# SN32F290 register map
Vendor: SONIX; File version: 2026.10.03
CPU: CM0 r0p0, little endian, no MPU, no FPU, 2 interrupt priority bits
Registers are 32-bit, read-write, reset 0x0 unless marked. A register's access mark holds for its fields unless they carry their own. Offsets are from the block's base; [hi:lo] are bit positions.

## SN_SPI0 — SPI0
Base 0x4001C000
0x00 CTRL0 reset 0x40F00 (reset mask 0x7FFDF) — Offset:0x00 SPI0 Control Register 0
  [36:18] SELDIS — Auto-SEL disable bit
    0=Enable_145 (Enable Auto-SEL flow control); 1=Disable_434 (Disable Auto-SEL flow control)
  [32:15] RXFIFOTH — RX FIFO Threshold level
    0=V_0_164 (RX FIFO threshold level is 0); 1=V_1_374 (RX FIFO threshold level is 1); 2=V_2 (RX FIFO threshold level is 2); 3=V_3_20 (RX FIFO threshold level is 3); 4=V_4_16 (RX FIFO threshold level is 4); 5=V_5 (RX FIFO threshold level is 5); 6=V_6_9 (RX FIFO threshold level is 6); 7=V_7_10 (RX FIFO threshold level is 7)
  [26:12] TXFIFOTH — TX FIFO Threshold level
    0=V_0_164 (TX FIFO threshold level is 0); 1=V_1_374 (TX FIFO threshold level is 1); 2=V_2 (TX FIFO threshold level is 2); 3=V_3_20 (TX FIFO threshold level is 3); 4=V_4_16 (TX FIFO threshold level is 4); 5=V_5 (TX FIFO threshold level is 5); 6=V_6_9 (TX FIFO threshold level is 6); 7=V_7_10 (TX FIFO threshold level is 7)
  [19:8] DL — Data length = DL[3:0]+1
    10=V_1010_2 (Data length=11); 11=V_1011_2 (Data length=12); 12=V_1100_6 (Data length=13); 13=V_1101_3 (Data length=14); 14=V_1110_5 (Data length=15); 15=V_1111 (Data length=16); 2=V_0010_2 (Data length=3); 3=V_0011_4 (Data length=4); 4=V_0100_6 (Data length=5); 5=V_0101_4 (Data length=6); 6=V_0110 (Data length=7); 7=V_0111_5 (Data length=8); 8=V_1000_3 (Data length=9); 9=V_1001_3 (Data length=10)
  [13:6] FRESET wo — SPI FSM and FIFO Reset
    0=V_00 (No effect); 3=V_11_3 (Reset FSM and FIFO)
  [8:4] FORMAT — Interface format
    0=SPI_2 (SPI format)
  [6:3] MS — Master/Slave selection
    0=Master_3 (Act as Master); 1=Slave_6 (Act as Slave)
  [4:2] SDODIS — Slave data out disable
    0=Enable_145 (Enable slave data out); 1=Disble_2 (Diable slave data out (MISO=0))
  [2:1] LOOPBACK — Loopback mode enable
    0=Disable_434 (Disable loopback mode); 1=Enable_145 (Enable loopback mode)
  [0] SPIEN — SPI enable
    0=Disable_434 (Disable SPI); 1=Enable_145 (Enable SPI)
0x04 CTRL1 (reset mask 0x7) — Offset:0x04 SPI0 Control Register 1
  [4:2] CPHA — Clock phase of edge sampling
    0=CPHA0_2 (The 1st bit is fixed already, and SCK 1st edge is to receive/transmit data); 1=CPHA1_2 (SCK 1st edge is for data transition, and receive/transmit data at 2nd edge)
  [2:1] CPOL — Clock priority selection
    0=Low_4 (SCK idles at low level); 1=High_23 (SCK idles at high level)
  [0] MLSB — MSB/LSB seletion
    0=MSB_2 (MSB transmit first); 1=LSB_2 (LSB transmit first)
0x08 CLKDIV — Offset:0x08 SPI0 Clock Divider Register
  [7:0] DIV — SPI0 SCK
0x0C STAT ro reset 0x25 (reset mask 0x7F) — Offset:0x0C SPI0 Status Register
  [12:6] RXFIFOTHF — RX FIFO threshold flag
    0=V_0_164 (Data count in RX FIFO is less equal than RXFIFOTH); 1=V_1_374 (Data count in RX FIFO is larger than RXFIFOTH)
  [10:5] TXFIFOTHF — TX FIFO threshold flag
    0=V_0_164 (Data count in TX FIFO is larger than TXFIFOTH); 1=V_1_374 (Data count in TX FIFO is less equal than TXFIFOTH)
  [8:4] BUSY — Busy flag
    0=Idle_6 (SSPn is idle); 1=SSPn is transfering
  [6:3] RX_FULL — RX FIFO full flag
    0=V_0_164 (RX FIFO is not full); 1=V_1_374 (RX FIFO is full)
  [4:2] RX_EMPTY — RX FIFO empty flag
    0=V_0_164 (RX FIFO is not empty); 1=V_1_374 (RX FIFO is empty)
  [2:1] TX_FULL — TX FIFO full flag
    0=V_0_164 (TX FIFO is not full); 1=V_1_374 (TX FIFO is full)
  [0] TX_EMPTY — TX FIFO empty flag
    0=V_0_164 (TX FIFO is not empty); 1=V_1_374 (TX FIFO is empty)
0x10 IE (reset mask 0x3F) — Offset:0x10 SPI0 Interrupt Enable Register
  [10:5] DMATCIE — DMA transfer complete interrupt enable bit
    0=Disable_434 (Disable DMA transfer complete interrupt); 1=Enable_145 (Enable DMA transfer complete interrupt)
  [8:4] DMAHTIE — DMA half transfer interrupt enable bit
    0=Disable_434 (Disable DMA half transfer interrupt); 1=Enable_145 (Enable DMA half transfer interrupt)
  [6:3] TXFIFOTHIE — TX FIFO threshold interrupt enable
    0=Disable_434 (Disable TX FIFO threshold interrupt); 1=Enable_145 (Enable TX FIFO threshold interrupt)
  [4:2] RXFIFOTHIE — RX FIFO threshold interrupt enable
    0=Disable_434 (Disable RX FIFO threshold interrupt); 1=Enable_145 (Enable RX FIFO threshold interrupt)
  [2:1] RXTOIE — RX time-out interrupt enable
    0=Disable_434 (Disable RX time-out interrupt); 1=Enable_145 (Enable RX time-out interrupt)
  [0] RXOVFIE — RX FIFO overflow interrupt enable
    0=Disable_434 (Disable RX FIFO overflow interrupt); 1=Enable_145 (Enable RX FIFO overflow interrupt)
0x14 RIS ro (reset mask 0x3F) — Offset:0x14 SPI0 Raw Interrupt Status Register
  [10:5] DMATCIF — DMA transfer complete flag
    0=No_58 (No transfer completion); 1=Met_12 (A transfer complete event occurs)
  [8:4] DMAHTIF — RX FIFO threshold interrupt flag
    0=No_58 (No half transfer event); 1=Met_12 (A half transfer event occurs)
  [6:3] TXFIFOTHIF — TX FIFO threshold interrupt flag
    0=No_58 (No TXFIFOTH interrupt); 1=Met_12 (TX FIFO threshold is triggered when TXFIFOTHIE=1)
  [4:2] RXFIFOTHIF — RX FIFO threshold interrupt flag
    0=No_58 (No RXFIFOTH interrupt); 1=Met_12 (RX FIFO threshold is triggered when RXFIFOTHIE=1)
  [2:1] RXTOIF — RX time-out interrupt flag
    0=No_58 (No RXTO interrupt); 1=Met_12 (RXTO interrupt is triggered when RXTOIE=1)
  [0] RXOVFIF — RX FIFO overflow interrupt flag
    0=No_58 (No RXOVF interrupt); 1=Met_12 (RXOVF interrupt is triggered when RXOVFIE=1)
0x18 IC wo (reset mask 0x3F) — Offset:0x18 SPI0 Interrupt Clear Register
  [10:5] DMATCIC — Select the DMATCIF flag to be cleared
    0=No_effect_200; 1=Clear_V_150 (Clear DMATCIF flag)
  [8:4] DMAHTIC — Select the DMAHTIF flag to be cleared
    0=No_effect_200; 1=Clear_V_150 (Clear DMAHTIF flag)
  [6:3] TXFIFOTHIC — TX Interrupt flag Clear
    0=No_effect_200; 1=Clear_V_150 (Clear TXFIFOTH flag)
  [4:2] RXFIFOTHIC — RX Interrupt flag Clear
    0=No_effect_200; 1=Clear_V_150 (Clear RXFIFOTH flag)
  [2:1] RXTOIC — RX time-out interrupt flag clear
    0=No_effect_200; 1=Clear_V_150 (Clear RXTO flag)
  [0] RXOVFIC — RX FIFO overflow flag clear
    0=No_effect_200; 1=Clear_V_150 (Clear RXOVF flag)
0x1C DATA — Offset:0x1C SPI0 Data Register
  [15:0] Data
0x20 DFDLY — Offset:0x20 SPI0 Data Fetch Register
  [0] DFETCH_EN — SPI0 data fetch control bit
    0=Disable_434; 1=Enable_145 (Enable when SCKn frequency is higher than 6MHz)
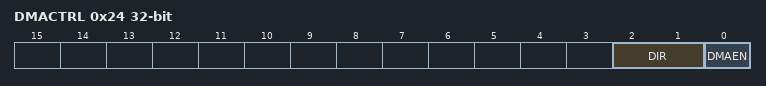
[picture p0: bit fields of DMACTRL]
0x24 DMACTRL (reset mask 0x3) — Offset:0x24 SPI0 DMA Control register
  [2:1] DIR — SPI data transfer direction
    0=SPI1toSPI0 (SPI1_DATA(RX) to SPI0_DATA(TX), when DMATCIE and DMAHTIE enable, and trigger SPI0 interrupt); 1=SPI0toSPI1 (SPI0_DATA(RX) to SPI1_DATA(TX) , when DMATCIE and DMAHTIE enable, and trigger SPI1 interrupt)
  [0] DMAEN — SPI to SPI DMA enable bit
    0=Disable_434; 1=Enable_145
0x28 DMACNT — Offset:0x28 SPI0 DMA Control register
  [27:0] CNT — Number of data to DMA RX count transfer
0x2C DMAHTCNT — Offset:0x2C SPI0 DMA Control register
  [27:0] HTCNT — Number of data to DMA RX half count transfer
0x30 CURCNT ro — Offset:0x30 SPI0 DMA Control register
  [27:0] CURCNT — This field indicates DMA current transfer data counter pointer.
